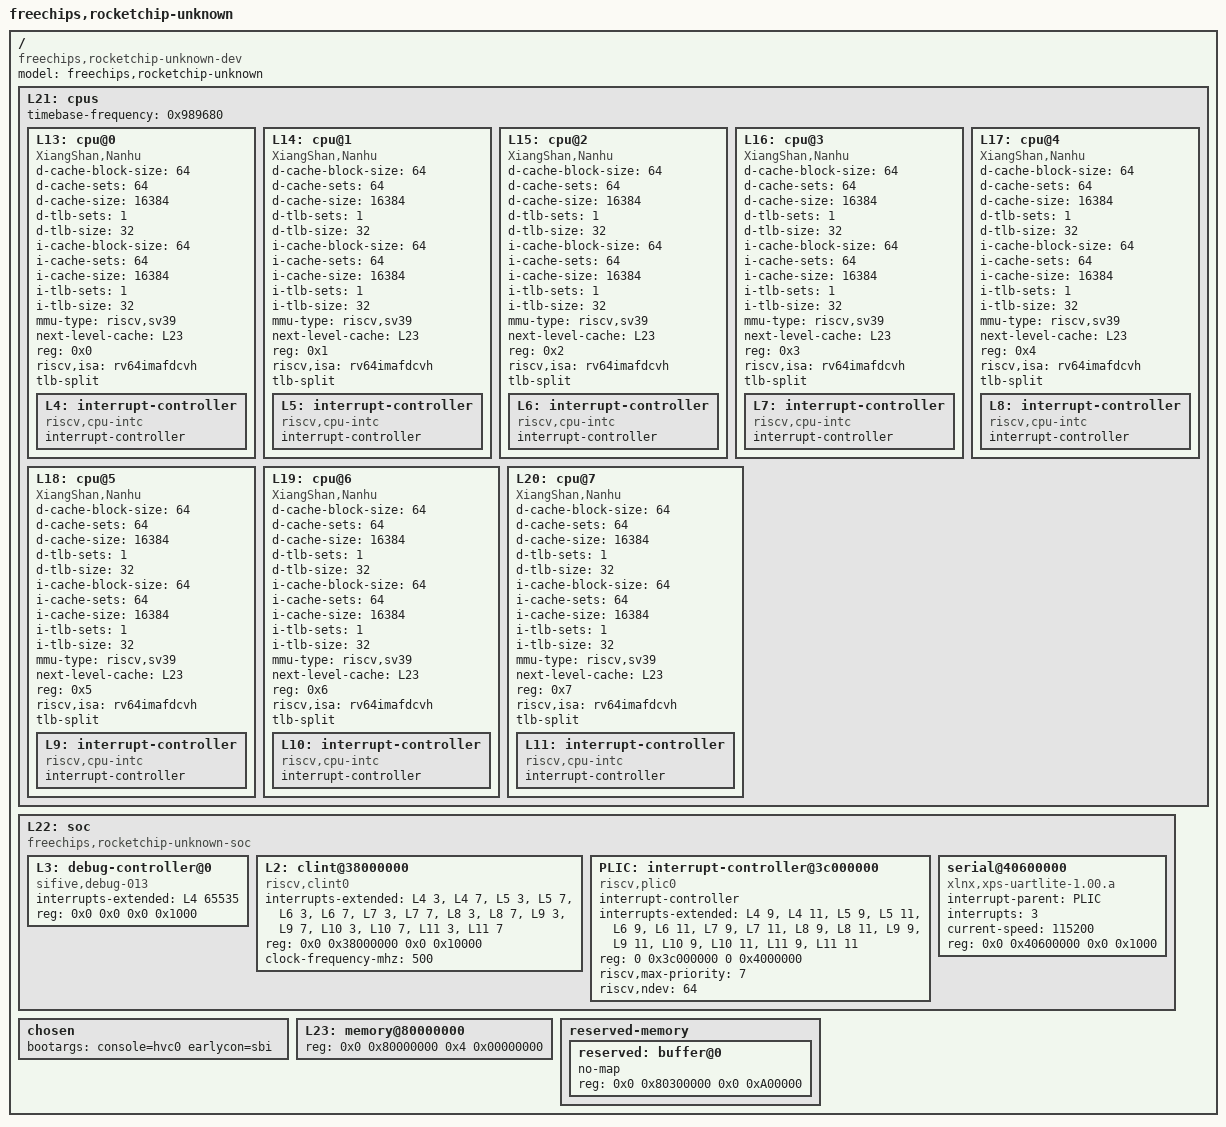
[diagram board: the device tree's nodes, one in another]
/dts-v1/;

/ {
	#address-cells = <2>;
	#size-cells = <2>;
	compatible = "freechips,rocketchip-unknown-dev";
	model = "freechips,rocketchip-unknown";
	L21: cpus {
		#address-cells = <1>;
		#size-cells = <0>;
		timebase-frequency = <0x989680>;
		L13: cpu@0 {
			compatible = "XiangShan,Nanhu", "riscv";
			d-cache-block-size = <64>;
			d-cache-sets = <64>;
			d-cache-size = <16384>;
			d-tlb-sets = <1>;
			d-tlb-size = <32>;
			device_type = "cpu";
			i-cache-block-size = <64>;
			i-cache-sets = <64>;
			i-cache-size = <16384>;
			i-tlb-sets = <1>;
			i-tlb-size = <32>;
			mmu-type = "riscv,sv39";
			next-level-cache = <&L23>;
			reg = <0x0>;
			riscv,isa = "rv64imafdcvh";
			status = "okay";
			tlb-split;
			L4: interrupt-controller {
				#interrupt-cells = <1>;
				compatible = "riscv,cpu-intc";
				interrupt-controller;
			};
		};
		L14: cpu@1 {
			compatible = "XiangShan,Nanhu", "riscv";
			d-cache-block-size = <64>;
			d-cache-sets = <64>;
			d-cache-size = <16384>;
			d-tlb-sets = <1>;
			d-tlb-size = <32>;
			device_type = "cpu";
			i-cache-block-size = <64>;
			i-cache-sets = <64>;
			i-cache-size = <16384>;
			i-tlb-sets = <1>;
			i-tlb-size = <32>;
			mmu-type = "riscv,sv39";
			next-level-cache = <&L23>;
			reg = <0x1>;
			riscv,isa = "rv64imafdcvh";
			status = "okay";
			tlb-split;
			L5: interrupt-controller {
				#interrupt-cells = <1>;
				compatible = "riscv,cpu-intc";
				interrupt-controller;
			};
		};
		L15: cpu@2 {
			compatible = "XiangShan,Nanhu", "riscv";
			d-cache-block-size = <64>;
			d-cache-sets = <64>;
			d-cache-size = <16384>;
			d-tlb-sets = <1>;
			d-tlb-size = <32>;
			device_type = "cpu";
			i-cache-block-size = <64>;
			i-cache-sets = <64>;
			i-cache-size = <16384>;
			i-tlb-sets = <1>;
			i-tlb-size = <32>;
			mmu-type = "riscv,sv39";
			next-level-cache = <&L23>;
			reg = <0x2>;
			riscv,isa = "rv64imafdcvh";
			status = "okay";
			tlb-split;
			L6: interrupt-controller {
				#interrupt-cells = <1>;
				compatible = "riscv,cpu-intc";
				interrupt-controller;
			};
		};
		L16: cpu@3 {
			compatible = "XiangShan,Nanhu", "riscv";
			d-cache-block-size = <64>;
			d-cache-sets = <64>;
			d-cache-size = <16384>;
			d-tlb-sets = <1>;
			d-tlb-size = <32>;
			device_type = "cpu";
			i-cache-block-size = <64>;
			i-cache-sets = <64>;
			i-cache-size = <16384>;
			i-tlb-sets = <1>;
			i-tlb-size = <32>;
			mmu-type = "riscv,sv39";
			next-level-cache = <&L23>;
			reg = <0x3>;
			riscv,isa = "rv64imafdcvh";
			status = "okay";
			tlb-split;
			L7: interrupt-controller {
				#interrupt-cells = <1>;
				compatible = "riscv,cpu-intc";
				interrupt-controller;
			};
		};
		L17: cpu@4 {
			compatible = "XiangShan,Nanhu", "riscv";
			d-cache-block-size = <64>;
			d-cache-sets = <64>;
			d-cache-size = <16384>;
			d-tlb-sets = <1>;
			d-tlb-size = <32>;
			device_type = "cpu";
			i-cache-block-size = <64>;
			i-cache-sets = <64>;
			i-cache-size = <16384>;
			i-tlb-sets = <1>;
			i-tlb-size = <32>;
			mmu-type = "riscv,sv39";
			next-level-cache = <&L23>;
			reg = <0x4>;
			riscv,isa = "rv64imafdcvh";
			status = "okay";
			tlb-split;
			L8: interrupt-controller {
				#interrupt-cells = <1>;
				compatible = "riscv,cpu-intc";
				interrupt-controller;
			};
		};
		L18: cpu@5 {
			compatible = "XiangShan,Nanhu", "riscv";
			d-cache-block-size = <64>;
			d-cache-sets = <64>;
			d-cache-size = <16384>;
			d-tlb-sets = <1>;
			d-tlb-size = <32>;
			device_type = "cpu";
			i-cache-block-size = <64>;
			i-cache-sets = <64>;
			i-cache-size = <16384>;
			i-tlb-sets = <1>;
			i-tlb-size = <32>;
			mmu-type = "riscv,sv39";
			next-level-cache = <&L23>;
			reg = <0x5>;
			riscv,isa = "rv64imafdcvh";
			status = "okay";
			tlb-split;
			L9: interrupt-controller {
				#interrupt-cells = <1>;
				compatible = "riscv,cpu-intc";
				interrupt-controller;
			};
		};
		L19: cpu@6 {
			compatible = "XiangShan,Nanhu", "riscv";
			d-cache-block-size = <64>;
			d-cache-sets = <64>;
			d-cache-size = <16384>;
			d-tlb-sets = <1>;
			d-tlb-size = <32>;
			device_type = "cpu";
			i-cache-block-size = <64>;
			i-cache-sets = <64>;
			i-cache-size = <16384>;
			i-tlb-sets = <1>;
			i-tlb-size = <32>;
			mmu-type = "riscv,sv39";
			next-level-cache = <&L23>;
			reg = <0x6>;
			riscv,isa = "rv64imafdcvh";
			status = "okay";
			tlb-split;
			L10: interrupt-controller {
				#interrupt-cells = <1>;
				compatible = "riscv,cpu-intc";
				interrupt-controller;
			};
		};
		L20: cpu@7 {
			compatible = "XiangShan,Nanhu", "riscv";
			d-cache-block-size = <64>;
			d-cache-sets = <64>;
			d-cache-size = <16384>;
			d-tlb-sets = <1>;
			d-tlb-size = <32>;
			device_type = "cpu";
			i-cache-block-size = <64>;
			i-cache-sets = <64>;
			i-cache-size = <16384>;
			i-tlb-sets = <1>;
			i-tlb-size = <32>;
			mmu-type = "riscv,sv39";
			next-level-cache = <&L23>;
			reg = <0x7>;
			riscv,isa = "rv64imafdcvh";
			status = "okay";
			tlb-split;
			L11: interrupt-controller {
				#interrupt-cells = <1>;
				compatible = "riscv,cpu-intc";
				interrupt-controller;
			};
		};
	};
	L22: soc {
		#address-cells = <2>;
		#size-cells = <2>;
		compatible = "freechips,rocketchip-unknown-soc", "simple-bus";
		ranges;
		L3: debug-controller@0 {
			compatible = "sifive,debug-013", "riscv,debug-013";
			interrupts-extended = <&L4 65535>;
			reg = <0x0 0x0 0x0 0x1000>;
			reg-names = "control";
		};
		L2: clint@38000000 {
			compatible = "riscv,clint0";
			interrupts-extended = <&L4 3 &L4 7 &L5 3 &L5 7 &L6 3 &L6 7 &L7 3 &L7 7 &L8 3 &L8 7 &L9 3 &L9 7 &L10 3 &L10 7 &L11 3 &L11 7>;
			reg = <0x0 0x38000000 0x0 0x10000>;
			reg-names = "control";
			clock-frequency-mhz = <500>;
		};
		PLIC: interrupt-controller@3c000000 {
			#interrupt-cells = <1>;
			compatible = "riscv,plic0";
			interrupt-controller;
			interrupts-extended = <&L4 9 &L4 11 &L5 9 &L5 11 &L6 9 &L6 11 &L7 9 &L7 11 &L8 9 &L8 11 &L9 9 &L9 11 &L10 9 &L10 11 &L11 9 &L11 11>;
			//interrupts-extended = <&L4 0xb &L4 0x9 &L5 0xb &L5 0x9>;
			//reg = <0 0xc000000 0 0x4000000>;
			reg = <0 0x3c000000 0 0x4000000>;
			reg-names = "control";
			riscv,max-priority = <7>;
			riscv,ndev = <64>;
		};
		serial@40600000 {
			compatible = "xlnx,xps-uartlite-1.00.a";
			interrupt-parent = <&PLIC>;
			interrupts = <3>;
			current-speed = <115200>;
			reg = <0x0 0x40600000 0x0 0x1000>;
			reg-names = "control";
		};
	};
	chosen {
		bootargs = "console=hvc0 earlycon=sbi ";
	};
	L23: memory@80000000 {
		device_type = "memory";
		reg = <0x0 0x80000000 0x4 0x00000000>;
	};
  reserved-memory {
    #address-cells = <2>;
    #size-cells = <2>;
    ranges;

    reserved: buffer@0{
      no-map;
      reg = <0x0 0x80300000 0x0 0xA00000>;
    };
  };
};
